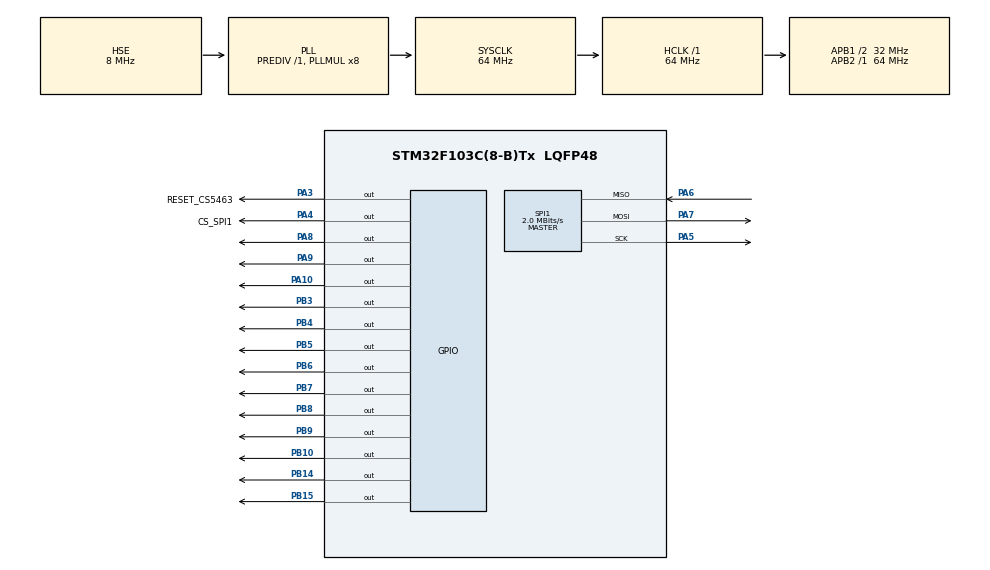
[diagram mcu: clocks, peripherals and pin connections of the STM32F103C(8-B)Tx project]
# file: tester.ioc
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Mcu.Family=STM32F1
Mcu.Name=STM32F103C(8-B)Tx
Mcu.Package=LQFP48
NVIC.PriorityGroup=NVIC_PRIORITYGROUP_4
NVIC.SPI1_IRQn=true\:0\:0\:false\:false\:true\:true
NVIC.TIM2_IRQn=true\:0\:0\:false\:false\:true\:true
PA10.Signal=GPIO_Output
PA13.Mode=Serial_Wire
PA13.Signal=SYS_JTMS-SWDIO
PA14.Mode=Serial_Wire
PA14.Signal=SYS_JTCK-SWCLK
PA3.GPIO_Label=RESET_CS5463
PA3.Signal=GPIO_Output
PA4.GPIO_Label=CS_SPI1
PA4.Signal=GPIO_Output
PA5.Mode=Full_Duplex_Master
PA5.Signal=SPI1_SCK
PA6.Mode=Full_Duplex_Master
PA6.Signal=SPI1_MISO
PA7.Mode=Full_Duplex_Master
PA7.Signal=SPI1_MOSI
PA8.Signal=GPIO_Output
PA9.Signal=GPIO_Output
PB10.Signal=GPIO_Output
PB14.Signal=GPIO_Output
PB15.Signal=GPIO_Output
PB3.Signal=GPIO_Output
PB4.Signal=GPIO_Output
PB5.Signal=GPIO_Output
PB6.Signal=GPIO_Output
PB7.Signal=GPIO_Output
PB8.Signal=GPIO_Output
PB9.Signal=GPIO_Output
PD0-OSC_IN.Mode=HSE-External-Oscillator
PD0-OSC_IN.Signal=RCC_OSC_IN
PD1-OSC_OUT.Mode=HSE-External-Oscillator
PD1-OSC_OUT.Signal=RCC_OSC_OUT
ProjectManager.HeapSize=0x200
ProjectManager.StackSize=0x400
ProjectManager.TargetToolchain=SW4STM32
RCC.ADCPresc=RCC_ADCPCLK2_DIV6
RCC.AHBFreq_Value=64000000
RCC.APB1CLKDivider=RCC_HCLK_DIV2
RCC.APB1Freq_Value=32000000
RCC.APB1TimFreq_Value=64000000
RCC.APB2Freq_Value=64000000
RCC.APB2TimFreq_Value=64000000
RCC.HCLKFreq_Value=64000000
RCC.PLLMUL=RCC_PLL_MUL8
RCC.PLLSourceVirtual=RCC_PLLSOURCE_HSE
RCC.SYSCLKFreq_VALUE=64000000
RCC.SYSCLKSource=RCC_SYSCLKSOURCE_PLLCLK
RCC.USBFreq_Value=64000000
SPI1.BaudRatePrescaler=SPI_BAUDRATEPRESCALER_32
SPI1.CLKPhase=SPI_PHASE_2EDGE
SPI1.CLKPolarity=SPI_POLARITY_HIGH
SPI1.CalculateBaudRate=2.0 MBits/s
SPI1.Direction=SPI_DIRECTION_2LINES
SPI1.Mode=SPI_MODE_MASTER
SPI1.VirtualType=VM_MASTER
TIM2.AutoReloadPreload=TIM_AUTORELOAD_PRELOAD_ENABLE
TIM2.Period=1000
TIM2.Prescaler=64
VP_TIM2_VS_ClockSourceINT.Mode=Internal
board=tester

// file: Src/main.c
/**
  ******************************************************************************
  * File Name          : main.c
  * Description        : Main program body
  ******************************************************************************
  ** This notice applies to any and all portions of this file
  * that are not between comment pairs USER CODE BEGIN and
  * USER CODE END. Other portions of this file, whether
  * inserted by the user or by software development tools
  * are owned by their respective copyright owners.
  *
  * COPYRIGHT(c) 2018 STMicroelectronics
  *
  * Redistribution and use in source and binary forms, with or without modification,
  * are permitted provided that the following conditions are met:
  *   1. Redistributions of source code must retain the above copyright notice,
  *      this list of conditions and the following disclaimer.
  *   2. Redistributions in binary form must reproduce the above copyright notice,
  *      this list of conditions and the following disclaimer in the documentation
  *      and/or other materials provided with the distribution.
  *   3. Neither the name of STMicroelectronics nor the names of its contributors
  *      may be used to endorse or promote products derived from this software
  *      without specific prior written permission.
  *
  * THIS SOFTWARE IS PROVIDED BY THE COPYRIGHT HOLDERS AND CONTRIBUTORS "AS IS"
  * AND ANY EXPRESS OR IMPLIED WARRANTIES, INCLUDING, BUT NOT LIMITED TO, THE
  * IMPLIED WARRANTIES OF MERCHANTABILITY AND FITNESS FOR A PARTICULAR PURPOSE ARE
  * DISCLAIMED. IN NO EVENT SHALL THE COPYRIGHT HOLDER OR CONTRIBUTORS BE LIABLE
  * FOR ANY DIRECT, INDIRECT, INCIDENTAL, SPECIAL, EXEMPLARY, OR CONSEQUENTIAL
  * DAMAGES (INCLUDING, BUT NOT LIMITED TO, PROCUREMENT OF SUBSTITUTE GOODS OR
  * SERVICES; LOSS OF USE, DATA, OR PROFITS; OR BUSINESS INTERRUPTION) HOWEVER
  * CAUSED AND ON ANY THEORY OF LIABILITY, WHETHER IN CONTRACT, STRICT LIABILITY,
  * OR TORT (INCLUDING NEGLIGENCE OR OTHERWISE) ARISING IN ANY WAY OUT OF THE USE
  * OF THIS SOFTWARE, EVEN IF ADVISED OF THE POSSIBILITY OF SUCH DAMAGE.
  *
  ******************************************************************************
  */

#include "main.h"
#include "stm32f1xx_hal.h"

/* USER CODE BEGIN Includes */
#include "MainLoop.h"
/* USER CODE END Includes */

SPI_HandleTypeDef hspi1;

TIM_HandleTypeDef htim2;

/* USER CODE BEGIN PV */
/* Private variables ---------------------------------------------------------*/

/* USER CODE END PV */

void SystemClock_Config(void);
static void MX_GPIO_Init(void);
static void MX_SPI1_Init(void);
static void MX_TIM2_Init(void);

/* USER CODE BEGIN PFP */
/* Private function prototypes -----------------------------------------------*/

/* USER CODE END PFP */

int main(void)
{

  /* MCU Configuration----------------------------------------------------------*/

  /* Reset of all peripherals, Initializes the Flash interface and the Systick. */
  HAL_Init();

  /* Configure the system clock */
  SystemClock_Config();

  /* Initialize all configured peripherals */
  MX_GPIO_Init();
  MX_SPI1_Init();
  MX_TIM2_Init();

  /* USER CODE BEGIN 2 */
    mainLoopInit();
  /* USER CODE END 2 */

  /* Infinite loop */
  while (1)
  {

  /* USER CODE BEGIN 3 */
      handleMainLoop();
  }
  /* USER CODE END 3 */

}

/** System Clock Configuration
*/
void SystemClock_Config(void)
{

  RCC_OscInitTypeDef RCC_OscInitStruct;
  RCC_ClkInitTypeDef RCC_ClkInitStruct;

    /**Initializes the CPU, AHB and APB busses clocks
    */
  RCC_OscInitStruct.OscillatorType = RCC_OSCILLATORTYPE_HSE;
  RCC_OscInitStruct.HSEState = RCC_HSE_ON;
  RCC_OscInitStruct.HSEPredivValue = RCC_HSE_PREDIV_DIV1;
  RCC_OscInitStruct.HSIState = RCC_HSI_ON;
  RCC_OscInitStruct.PLL.PLLState = RCC_PLL_ON;
  RCC_OscInitStruct.PLL.PLLSource = RCC_PLLSOURCE_HSE;
  RCC_OscInitStruct.PLL.PLLMUL = RCC_PLL_MUL8;
  if (HAL_RCC_OscConfig(&RCC_OscInitStruct) != HAL_OK)
  {
    _Error_Handler(__FILE__, __LINE__);
  }

    /**Initializes the CPU, AHB and APB busses clocks
    */
  RCC_ClkInitStruct.ClockType = RCC_CLOCKTYPE_HCLK|RCC_CLOCKTYPE_SYSCLK
                              |RCC_CLOCKTYPE_PCLK1|RCC_CLOCKTYPE_PCLK2;
  RCC_ClkInitStruct.SYSCLKSource = RCC_SYSCLKSOURCE_PLLCLK;
  RCC_ClkInitStruct.AHBCLKDivider = RCC_SYSCLK_DIV1;
  RCC_ClkInitStruct.APB1CLKDivider = RCC_HCLK_DIV2;
  RCC_ClkInitStruct.APB2CLKDivider = RCC_HCLK_DIV1;

  if (HAL_RCC_ClockConfig(&RCC_ClkInitStruct, FLASH_LATENCY_2) != HAL_OK)
  {
    _Error_Handler(__FILE__, __LINE__);
  }

    /**Configure the Systick interrupt time
    */
  HAL_SYSTICK_Config(HAL_RCC_GetHCLKFreq()/1000);

    /**Configure the Systick
    */
  HAL_SYSTICK_CLKSourceConfig(SYSTICK_CLKSOURCE_HCLK);

  /* SysTick_IRQn interrupt configuration */
  HAL_NVIC_SetPriority(SysTick_IRQn, 0, 0);
}

/* SPI1 init function */
static void MX_SPI1_Init(void)
{

  /* SPI1 parameter configuration*/
  hspi1.Instance = SPI1;
  hspi1.Init.Mode = SPI_MODE_MASTER;
  hspi1.Init.Direction = SPI_DIRECTION_2LINES;
  hspi1.Init.DataSize = SPI_DATASIZE_8BIT;
  hspi1.Init.CLKPolarity = SPI_POLARITY_HIGH;
  hspi1.Init.CLKPhase = SPI_PHASE_2EDGE;
  hspi1.Init.NSS = SPI_NSS_SOFT;
  hspi1.Init.BaudRatePrescaler = SPI_BAUDRATEPRESCALER_32;
  hspi1.Init.FirstBit = SPI_FIRSTBIT_MSB;
  hspi1.Init.TIMode = SPI_TIMODE_DISABLE;
  hspi1.Init.CRCCalculation = SPI_CRCCALCULATION_DISABLE;
  hspi1.Init.CRCPolynomial = 10;
  if (HAL_SPI_Init(&hspi1) != HAL_OK)
  {
    _Error_Handler(__FILE__, __LINE__);
  }

}

/* TIM2 init function */
static void MX_TIM2_Init(void)
{

  TIM_ClockConfigTypeDef sClockSourceConfig;
  TIM_MasterConfigTypeDef sMasterConfig;

  htim2.Instance = TIM2;
  htim2.Init.Prescaler = 64;
  htim2.Init.CounterMode = TIM_COUNTERMODE_UP;
  htim2.Init.Period = 1000;
  htim2.Init.ClockDivision = TIM_CLOCKDIVISION_DIV1;
  htim2.Init.AutoReloadPreload = TIM_AUTORELOAD_PRELOAD_ENABLE;
  if (HAL_TIM_Base_Init(&htim2) != HAL_OK)
  {
    _Error_Handler(__FILE__, __LINE__);
  }

  sClockSourceConfig.ClockSource = TIM_CLOCKSOURCE_INTERNAL;
  if (HAL_TIM_ConfigClockSource(&htim2, &sClockSourceConfig) != HAL_OK)
  {
    _Error_Handler(__FILE__, __LINE__);
  }

  sMasterConfig.MasterOutputTrigger = TIM_TRGO_RESET;
  sMasterConfig.MasterSlaveMode = TIM_MASTERSLAVEMODE_DISABLE;
  if (HAL_TIMEx_MasterConfigSynchronization(&htim2, &sMasterConfig) != HAL_OK)
  {
    _Error_Handler(__FILE__, __LINE__);
  }

}

/** Configure pins as
        * Analog
        * Input
        * Output
        * EVENT_OUT
        * EXTI
*/
static void MX_GPIO_Init(void)
{

  GPIO_InitTypeDef GPIO_InitStruct;

  /* GPIO Ports Clock Enable */
  __HAL_RCC_GPIOD_CLK_ENABLE();
  __HAL_RCC_GPIOA_CLK_ENABLE();
  __HAL_RCC_GPIOB_CLK_ENABLE();

  /*Configure GPIO pin Output Level */
  HAL_GPIO_WritePin(GPIOA, RESET_CS5463_Pin|CS_SPI1_Pin|GPIO_PIN_8|GPIO_PIN_9
                          |GPIO_PIN_10, GPIO_PIN_RESET);

  /*Configure GPIO pin Output Level */
  HAL_GPIO_WritePin(GPIOB, GPIO_PIN_10|GPIO_PIN_14|GPIO_PIN_15|GPIO_PIN_3
                          |GPIO_PIN_4|GPIO_PIN_5|GPIO_PIN_6|GPIO_PIN_7
                          |GPIO_PIN_8|GPIO_PIN_9, GPIO_PIN_RESET);

  /*Configure GPIO pins : RESET_CS5463_Pin CS_SPI1_Pin PA8 PA9
                           PA10 */
  GPIO_InitStruct.Pin = RESET_CS5463_Pin|CS_SPI1_Pin|GPIO_PIN_8|GPIO_PIN_9
                          |GPIO_PIN_10;
  GPIO_InitStruct.Mode = GPIO_MODE_OUTPUT_PP;
  GPIO_InitStruct.Speed = GPIO_SPEED_FREQ_LOW;
  HAL_GPIO_Init(GPIOA, &GPIO_InitStruct);

  /*Configure GPIO pins : PB10 PB14 PB15 PB3
                           PB4 PB5 PB6 PB7
                           PB8 PB9 */
  GPIO_InitStruct.Pin = GPIO_PIN_10|GPIO_PIN_14|GPIO_PIN_15|GPIO_PIN_3
                          |GPIO_PIN_4|GPIO_PIN_5|GPIO_PIN_6|GPIO_PIN_7
                          |GPIO_PIN_8|GPIO_PIN_9;
  GPIO_InitStruct.Mode = GPIO_MODE_OUTPUT_PP;
  GPIO_InitStruct.Speed = GPIO_SPEED_FREQ_LOW;
  HAL_GPIO_Init(GPIOB, &GPIO_InitStruct);

}

void _Error_Handler(char * file, int line)
{
  while(1)
  {
  }
}

/************************ (C) COPYRIGHT STMicroelectronics *****END OF FILE****/
